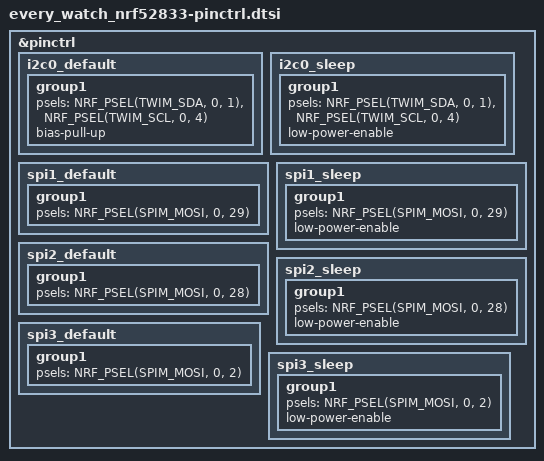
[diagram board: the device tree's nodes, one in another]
#include <dt-bindings/pinctrl/nrf-pinctrl.h>

&pinctrl {
	/* I2C0 (TWIM0 @ 0x40003000): SDA=P0.01, SCL=P0.04
	 * NOTE: TWIM0 and SPIM0 share the same hardware instance. Since I2C0 is
	 * enabled, SPI0 must remain disabled — it cannot be used simultaneously. */
	i2c0_default: i2c0_default {
		group1 {
			psels = <NRF_PSEL(TWIM_SDA, 0, 1)>,
				<NRF_PSEL(TWIM_SCL, 0, 4)>;
			/* WORKAROUND: no external I2C pull-up resistors are fitted
			 * on this revision of the PCB. Measured 2026-07-31 — both
			 * lines sit at 0 with the CPU halted and float high as soon
			 * as the internal pull-ups are enabled. Without these the
			 * bus cannot work at all: I2C is open-drain, so nothing ever
			 * pulls the lines high and every transfer times out.
			 *
			 * The nRF internal pull-ups are only ~13k, giving roughly a
			 * 1 us rise time. That is inside the 1 us budget for 100 kHz
			 * standard mode but far outside the 300 ns that 400 kHz fast
			 * mode needs — hence clock-frequency is dropped to
			 * I2C_BITRATE_STANDARD in the board DTS.
			 *
			 * Proper fix is 2.2k-4.7k resistors to VDD on SDA and SCL on
			 * the next board revision, after which these lines and the
			 * bitrate reduction can both be reverted. */
			bias-pull-up;
		};
	};
	i2c0_sleep: i2c0_sleep {
		group1 {
			psels = <NRF_PSEL(TWIM_SDA, 0, 1)>,
				<NRF_PSEL(TWIM_SCL, 0, 4)>;
			low-power-enable;
		};
	};

	/* SPI1 (SPIM1 @ 0x40004000): LED rows 0-1, MOSI=P0.29
	 * Drives 40 LEDs (snake: row 0 L→R idx 0-19, row 1 R→L idx 20-39) */
	spi1_default: spi1_default {
		group1 {
			psels = <NRF_PSEL(SPIM_MOSI, 0, 29)>;
		};
	};
	spi1_sleep: spi1_sleep {
		group1 {
			psels = <NRF_PSEL(SPIM_MOSI, 0, 29)>;
			low-power-enable;
		};
	};

	/* SPI2 (SPIM2 @ 0x40023000): LED rows 2-3, MOSI=P0.28
	 * Drives 40 LEDs (snake: row 2 L→R idx 0-19, row 3 R→L idx 20-39) */
	spi2_default: spi2_default {
		group1 {
			psels = <NRF_PSEL(SPIM_MOSI, 0, 28)>;
		};
	};
	spi2_sleep: spi2_sleep {
		group1 {
			psels = <NRF_PSEL(SPIM_MOSI, 0, 28)>;
			low-power-enable;
		};
	};

	/* SPI3 (SPIM3 @ 0x4002F000): LED rows 4-5, MOSI=P0.02
	 * Drives 40 LEDs (snake: row 4 L→R idx 0-19, row 5 R→L idx 20-39)
	 * Row 6 (P0.03, 20 LEDs) uses bitbang after this DMA transfer completes.
	 * SPIM0/TWIM0 share hardware at 0x40003000 so SPIM0 cannot be used while
	 * I2C0 is active — SPI0 is disabled in the DTS for this reason. */
	spi3_default: spi3_default {
		group1 {
			psels = <NRF_PSEL(SPIM_MOSI, 0, 2)>;
		};
	};
	spi3_sleep: spi3_sleep {
		group1 {
			psels = <NRF_PSEL(SPIM_MOSI, 0, 2)>;
			low-power-enable;
		};
	};
};
